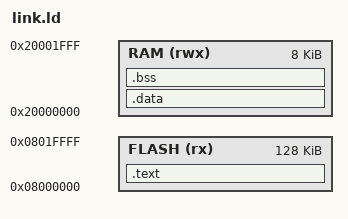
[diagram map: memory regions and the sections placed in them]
ENTRY(Reset_Handler)

MEMORY {
    FLASH (rx)  : ORIGIN = 0x08000000, LENGTH = 128K
    RAM   (rwx) : ORIGIN = 0x20000000, LENGTH = 8K
}

SECTIONS {
    .text : {
        KEEP(*(.vectors))
        *(.text .text.*)
        *(.rodata .rodata.*)
        . = ALIGN(4);
    } > FLASH

    _etext = .;

    .data : AT(_etext) {
        _sdata = .;
        *(.data .data.*)
        . = ALIGN(4);
        _edata = .;
    } > RAM

    .bss (NOLOAD) : {
        _sbss = .;
        *(.bss .bss.*)
        *(COMMON)
        . = ALIGN(4);
        _ebss = .;
    } > RAM

    _estack = ORIGIN(RAM) + LENGTH(RAM);
}
